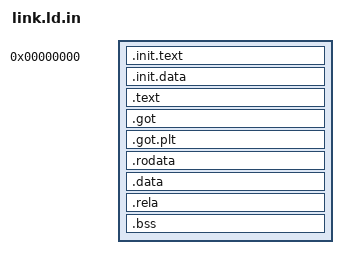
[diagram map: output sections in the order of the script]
/*
 * SPDX-FileCopyrightText: (C) Alex Smith <alex@alex-smith.me.uk>
 * SPDX-License-Identifier: ISC
 */

/**
 * @file
 * @brief               DT ARM64 loader linker script.
 */

#include <arch/page.h>

#include <platform/loader.h>

OUTPUT_FORMAT("elf64-littleaarch64")
OUTPUT_ARCH("aarch64")
ENTRY(loader_entry)

SECTIONS {
    . = 0;
    __start = .;

    /* Init code in start.S must be placed first: execution begins from the very
     * start of the loader image. */
    .init.text : { *(.init.text) }
    .init.data : { *(.init.data) }

    .text ALIGN(32) : {
        *(.text)
        *(.text.*)
    }

    .got ALIGN(32) : { *(.got) }
    .got.plt ALIGN(32) : { *(.got.plt) }

    .rodata ALIGN(32) : {
        *(.rodata)
        *(.rodata.*)
    }

    .data ALIGN(32) : {
        *(.data)
        *(.data.*)

        __builtins_start = .;
        *(.builtins)
        __builtins_end = .;

        __data_end = .;
    }

    .rela ALIGN(32) : {
        __rela_start = .;
        *(.rela)
        *(.rela.*)
        __rela_end = .;
    }

    .bss ALIGN(32) : {
        __bss_start = .;
        *(.bss)
        *(.bss.*)
        *(COMMON)
        __bss_end = .;
    }

    . = ALIGN(PAGE_SIZE);
    __end = .;

    __image_size = __end - __start;

    /DISCARD/ : {
        *(.note.*)
        *(.comment*)
        *(.eh_frame*)
        *(.interp)
        *(.dynamic)
        *(.dynsym)
        *(.dynstr)
        *(.hash)
        *(.gnu.hash)
    }
}
